VERSION ""

NS_ :

BS_:

BU_:

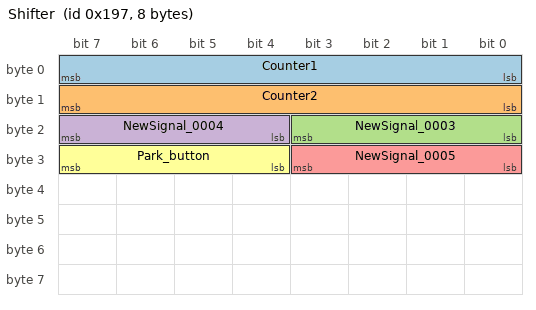
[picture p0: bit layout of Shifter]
BO_ 407 Shifter: 8 Vector__XXX
 SG_ Counter1 : 0|8@1+ (1,0) [0|0] "" Vector__XXX
 SG_ Counter2 : 8|8@1+ (1,0) [0|0] "" Vector__XXX
 SG_ NewSignal_0003 : 16|4@1+ (1,0) [0|0] "" Vector__XXX
 SG_ NewSignal_0004 : 20|4@1+ (1,0) [0|0] "" Vector__XXX
 SG_ NewSignal_0005 : 24|4@1+ (1,0) [0|0] "" Vector__XXX
 SG_ Park_button : 28|4@1+ (1,0) [0|1] "I/O" Vector__XXX

CM_ BO_ 407 "Shifter positions and buttons";
CM_ SG_ 407 Counter1 "Counter?
";
CM_ SG_ 407 Counter2 "Counter?";
VAL_ 407 Park_button 0 "Not pressed" 1 "Pressed" ;
